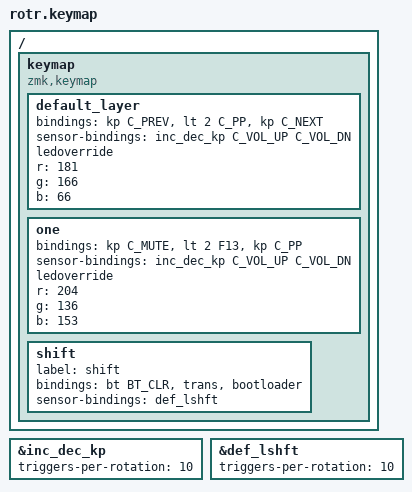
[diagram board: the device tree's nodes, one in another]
#include <behaviors.dtsi>
#include <dt-bindings/zmk/keys.h>
#include <dt-bindings/zmk/rgb.h>
#include <dt-bindings/zmk/bt.h>

&inc_dec_kp {
	triggers-per-rotation = <10>;
};
&def_lshft {
	triggers-per-rotation = <10>;
};

/ {
	keymap {
		compatible = "zmk,keymap";

		// guide: https://docs.google.com/document/d/1nOHC0R_G6HR0cCJJgpj22CC5Q_K_o-7oYNo1CTE4pvk/
		// discord: https://discord.com/channels/729010394756153384/729015812580704316

		default_layer {

			/////////////////// layer 0 ///////////////////
			// 
			////// default media controls
			//
			// F1: Previous Track
			// F2: Play / Pause 
			//	long press -> switch: https://zmk.dev/docs/behaviors/layers#behavior-binding-1
			// F3: Next Track
			//
			/////////////////// layer 0 ///////////////////

			bindings = <&kp C_PREV &lt 2 C_PP &kp C_NEXT>;
			sensor-bindings = <&inc_dec_kp C_VOL_UP C_VOL_DN>;
			ledoverride;
			// brass
			r = <181>;
			g = <166>;
			b = <66>;

		};

		one {

			/////////////////// layer 1 ///////////////////
			// 
			////// 2nd vendor default layer (Livid's original)
			// 	https://discord.com/channels/729010394756153384/729015812580704316/981159171586146314
			//
			// F1: Mute / Unmute Sound
			// F2: F13
			//	long press -> switch: https://zmk.dev/docs/behaviors/layers#behavior-binding-1
			// F3: Play / Pause
			//
			/////////////////// layer 1 ///////////////////

			bindings = <&kp C_MUTE &lt 2 F13 &kp C_PP>;
			sensor-bindings = <&inc_dec_kp C_VOL_UP C_VOL_DN>;
			ledoverride;
			// purple
			r = <204>;
			g = <136>;
			b = <153>;

		};

		shift {

			/////////////////// layer 2 ///////////////////
			//
			////// select from available layers
			//
			// F1: Bluetooth Clear Bond
			// 	https://zmk.dev/docs/behaviors/bluetooth
			// F2: Transparent 
			// 	hold key and turn knob to switch between layers
			// F3: Enter BootLoader mode
			// 	instead of pressing the physical reset button twice
			//	https://zmk.dev/docs/behaviors/reset
			//
			/////////////////// layer 2 ///////////////////

			// https://discord.com/channels/729010394756153384/729015812580704316/995791016131039485
			label = "shift";
			bindings = <&bt BT_CLR &trans &bootloader>;
			sensor-bindings = <&def_lshft>;

		};
	};
};
